VERSION ""

NS_ :

BS_:

BU_: Inverter_A Inverter_B MCU_Aux_A MCU_Aux_B CLU

BO_ 3221225472 VECTOR__INDEPENDENT_SIG_MSG: 0 Vector__XXX
 SG_ TurnOnOff : 0|8@1+ (1,0) [0|0] ""  Inverter_B
 SG_ Tuning_8 : 56|8@1+ (1,0) [0|0] ""  Inverter_A
 SG_ Tuning_7 : 48|8@1+ (1,0) [0|0] ""  Inverter_A
 SG_ Tuning_8 : 56|8@1+ (1,0) [0|0] ""  Inverter_B
 SG_ Tuning_7 : 48|8@1+ (1,0) [0|0] ""  Inverter_B
 SG_ TempPH2 : 0|1@1+ (1,0) [0|0] "degC" Vector__XXX
 SG_ TempPH3 : 0|1@1+ (1,0) [0|0] "degC" Vector__XXX

BO_ 16 TurnOnOffM1: 1 CLU
 SG_ Init : 0|1@1+ (1,0) [0|0] ""  Inverter_A
 SG_ Modulate : 1|1@1+ (1,0) [0|0] ""  Inverter_A

BO_ 32 TorqueReqSpeedLimitM1: 8 CLU
 SG_ Torque_Req : 0|32@1- (1000,0) [0|0] "Nm"  Inverter_A
 SG_ Speed_Req : 32|32@1- (1000,0) [0|0] "RPS"  Inverter_A

BO_ 33 TorqueReqSpeedLimitM2: 8 CLU
 SG_ Torque_Req : 0|32@1- (1000,0) [0|0] "Nm"  Inverter_B
 SG_ Speed_Req : 32|32@1- (1000,0) [0|0] "RPS"  Inverter_B

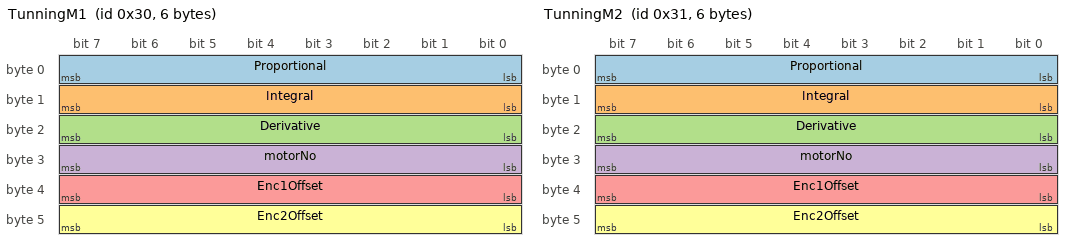
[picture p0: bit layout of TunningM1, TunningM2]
BO_ 48 TunningM1: 6 CLU
 SG_ Proportional : 0|8@1+ (100,0) [0|0] ""  Inverter_A
 SG_ Integral : 8|8@1+ (100,0) [0|0] ""  Inverter_A
 SG_ Derivative : 16|8@1+ (100,0) [0|0] ""  Inverter_A
 SG_ motorNo : 24|8@1+ (1,256) [0|0] ""  Inverter_A
 SG_ Enc1Offset : 32|8@1+ (1,256) [0|0] "LSB"  Inverter_A
 SG_ Enc2Offset : 40|8@1+ (1,256) [0|0] "LSB"  Inverter_A

BO_ 49 TunningM2: 6 CLU
 SG_ Proportional : 0|8@1+ (100,0) [0|0] ""  Inverter_B
 SG_ Integral : 8|8@1+ (100,0) [0|0] ""  Inverter_B
 SG_ Derivative : 16|8@1+ (100,0) [0|0] ""  Inverter_B
 SG_ motorNo : 24|8@1+ (1,0) [0|0] ""  Inverter_B
 SG_ Enc1Offset : 32|8@1+ (1,256) [0|0] "LSB"  Inverter_B
 SG_ Enc2Offset : 40|8@1+ (1,256) [0|0] "LSB"  Inverter_B

BO_ 256 FlowSensorM1: 8 MCU_Aux_A

BO_ 257 FlowSensorM2: 8 MCU_Aux_B

BO_ 64 TorqueDBrakingM1: 8 Inverter_A
 SG_ Torque_D_Output : 0|32@1- (1000,0) [0|0] "Nm"  Inverter_A,CLU

BO_ 65 TorqueDBrakingM2: 8 Inverter_B
 SG_ Torque_D_Output : 0|32@1- (1000,0) [0|0] "Nm"  Inverter_B,CLU

BO_ 80 TorqueSpeedAchievedM1: 8 Inverter_A
 SG_ Torque : 0|32@1- (1000,0) [0|0] "Nm"  CLU
 SG_ Speed : 32|32@1- (1000,0) [0|0] "RPS"  CLU

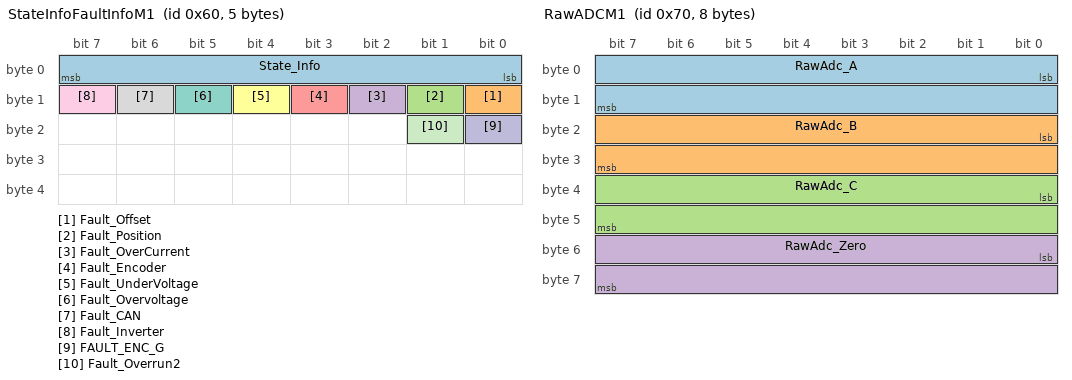
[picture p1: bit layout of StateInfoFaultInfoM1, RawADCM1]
BO_ 96 StateInfoFaultInfoM1: 5 Inverter_A
 SG_ State_Info : 0|8@1- (1,0) [0|0] ""  CLU
 SG_ Fault_Offset : 8|1@1- (1,0) [0|0] ""  CLU
 SG_ Fault_Position : 9|1@1+ (1,0) [0|0] ""  CLU
 SG_ Fault_OverCurrent : 10|1@1+ (1,0) [0|0] ""  CLU
 SG_ Fault_Encoder : 11|1@1+ (1,0) [0|0] ""  CLU
 SG_ Fault_UnderVoltage : 12|1@1+ (1,0) [0|0] ""  CLU
 SG_ Fault_Overvoltage : 13|1@1+ (1,0) [0|0] ""  CLU
 SG_ Fault_CAN : 14|1@1+ (1,0) [0|0] ""  CLU
 SG_ Fault_Inverter : 15|1@1+ (1,0) [0|0] ""  CLU
 SG_ FAULT_ENC_G : 16|1@1+ (1,0) [0|0] ""  CLU
 SG_ Fault_Overrun2 : 17|1@1+ (1,0) [0|0] ""  CLU

BO_ 112 RawADCM1: 8 Inverter_A
 SG_ RawAdc_A : 0|16@1+ (1,0) [0|0] ""  CLU
 SG_ RawAdc_B : 16|16@1+ (1,0) [0|0] ""  CLU
 SG_ RawAdc_C : 32|16@1+ (1,0) [0|0] ""  CLU
 SG_ RawAdc_Zero : 48|16@1- (1,0) [0|0] ""  CLU

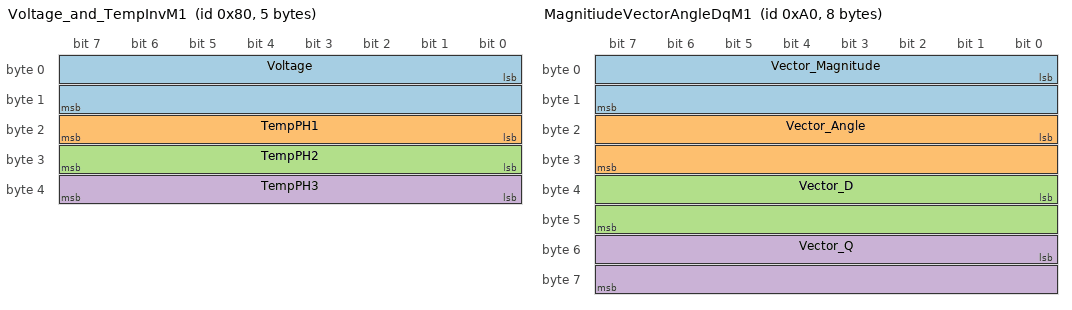
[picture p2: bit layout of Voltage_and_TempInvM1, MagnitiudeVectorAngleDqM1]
BO_ 128 Voltage_and_TempInvM1: 5 Inverter_A
 SG_ Voltage : 0|16@1+ (1,0) [0|0] "V"  CLU
 SG_ TempPH1 : 16|8@1+ (1,0) [0|0] "degC"  CLU
 SG_ TempPH2 : 24|8@1+ (1,0) [0|0] "degC"  CLU
 SG_ TempPH3 : 32|8@1+ (1,0) [0|0] "degC"  CLU

BO_ 160 MagnitiudeVectorAngleDqM1: 8 Inverter_A
 SG_ Vector_Magnitude : 0|16@1- (10000,0) [0|0] ""  CLU
 SG_ Vector_Angle : 16|16@1- (1000,0) [0|0] ""  CLU
 SG_ Vector_D : 32|16@1- (10000,0) [0|0] ""  CLU
 SG_ Vector_Q : 48|16@1- (10000,0) [0|0] ""  CLU

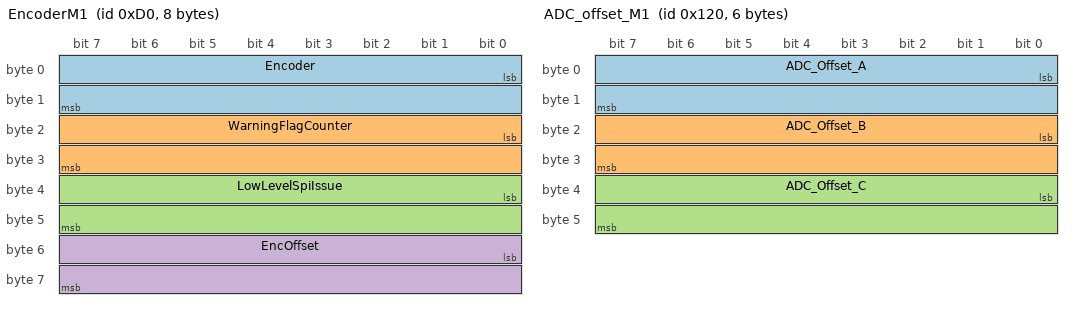
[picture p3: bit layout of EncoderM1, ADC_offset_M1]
BO_ 208 EncoderM1: 8 Inverter_A
 SG_ Encoder : 0|16@1+ (1,0) [0|0] "LSB"  CLU
 SG_ WarningFlagCounter : 16|16@1+ (1,0) [0|0] ""  CLU
 SG_ LowLevelSpiIssue : 32|16@1+ (1,0) [0|0] ""  CLU
 SG_ EncOffset : 48|16@1+ (1,0) [0|0] "LSB"  CLU

BO_ 288 ADC_offset_M1: 6 Inverter_A
 SG_ ADC_Offset_A : 0|16@1+ (1,0) [0|0] ""  CLU
 SG_ ADC_Offset_B : 16|16@1+ (1,0) [0|0] ""  CLU
 SG_ ADC_Offset_C : 32|16@1+ (1,0) [0|0] ""  CLU

BO_ 304 BuildInfo1_M1: 8 Inverter_A
 SG_ SiliconUID : 0|32@1+ (1,0) [0|0] ""  CLU
 SG_ BuildVersionSimulinkAfterDecimal : 32|32@1+ (1,0) [0|0] ""  CLU

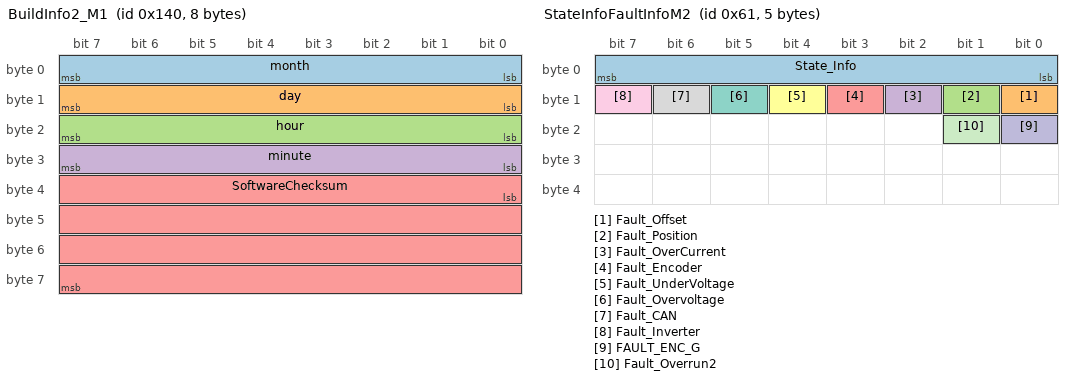
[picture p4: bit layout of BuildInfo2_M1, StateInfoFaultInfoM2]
BO_ 320 BuildInfo2_M1: 8 Inverter_A
 SG_ month : 0|8@1+ (1,0) [0|0] ""  CLU
 SG_ day : 8|8@1+ (1,0) [0|0] ""  CLU
 SG_ hour : 16|8@1+ (1,0) [0|0] ""  CLU
 SG_ minute : 24|8@1+ (1,0) [0|0] ""  CLU
 SG_ SoftwareChecksum : 32|32@1+ (1,0) [0|0] ""  CLU

BO_ 528 PidOutputM1: 8 Inverter_A
 SG_ PID_Output_D : 0|32@1- (1e-09,0) [0|0] "PU"  CLU
 SG_ PID_Output_Q : 32|32@1- (1e-09,0) [0|0] "PU"  CLU

BO_ 81 TorqueSpeedAchievedM2: 8 Inverter_B
 SG_ Torque : 0|32@1- (1000,0) [0|0] "Nm"  CLU
 SG_ Speed : 32|32@1- (1000,0) [0|0] "RPS"  CLU

BO_ 97 StateInfoFaultInfoM2: 5 Inverter_B
 SG_ State_Info : 0|8@1- (1,0) [0|0] ""  CLU
 SG_ Fault_Offset : 8|1@1- (1,0) [0|0] ""  CLU
 SG_ Fault_Position : 9|1@1+ (1,0) [0|0] ""  CLU
 SG_ Fault_OverCurrent : 10|1@1+ (1,0) [0|0] ""  CLU
 SG_ Fault_Encoder : 11|1@1+ (1,0) [0|0] ""  CLU
 SG_ Fault_UnderVoltage : 12|1@1+ (1,0) [0|0] ""  CLU
 SG_ Fault_Overvoltage : 13|1@1+ (1,0) [0|0] ""  CLU
 SG_ Fault_CAN : 14|1@1+ (1,0) [0|0] ""  CLU
 SG_ Fault_Inverter : 15|1@1+ (1,0) [0|0] ""  CLU
 SG_ FAULT_ENC_G : 16|1@1+ (1,0) [0|0] ""  CLU
 SG_ Fault_Overrun2 : 17|1@1+ (1,0) [0|0] ""  CLU

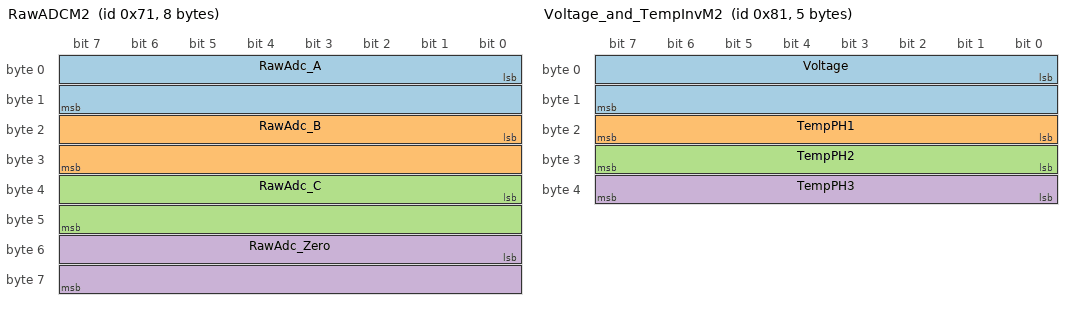
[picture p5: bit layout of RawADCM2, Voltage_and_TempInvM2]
BO_ 113 RawADCM2: 8 Inverter_B
 SG_ RawAdc_A : 0|16@1+ (1,0) [0|0] ""  CLU
 SG_ RawAdc_B : 16|16@1+ (1,0) [0|0] ""  CLU
 SG_ RawAdc_C : 32|16@1+ (1,0) [0|0] ""  CLU
 SG_ RawAdc_Zero : 48|16@1- (1,0) [0|0] ""  CLU

BO_ 129 Voltage_and_TempInvM2: 5 Inverter_B
 SG_ Voltage : 0|16@1+ (1,0) [0|0] "V"  CLU
 SG_ TempPH1 : 16|8@1+ (1,0) [0|0] "degC"  CLU
 SG_ TempPH2 : 24|8@1+ (1,0) [0|0] "degC"  CLU
 SG_ TempPH3 : 32|8@1+ (1,0) [0|0] "degC"  CLU

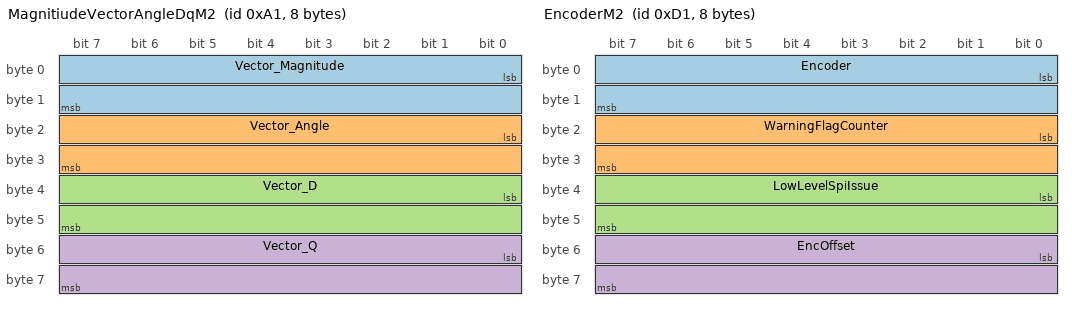
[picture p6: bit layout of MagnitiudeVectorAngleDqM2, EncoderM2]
BO_ 161 MagnitiudeVectorAngleDqM2: 8 Inverter_B
 SG_ Vector_Magnitude : 0|16@1- (10000,0) [0|0] ""  CLU
 SG_ Vector_Angle : 16|16@1- (1000,0) [0|0] ""  CLU
 SG_ Vector_D : 32|16@1- (10000,0) [0|0] ""  CLU
 SG_ Vector_Q : 48|16@1- (10000,0) [0|0] ""  CLU

BO_ 209 EncoderM2: 8 Inverter_B
 SG_ Encoder : 0|16@1+ (1,0) [0|0] "LSB"  CLU
 SG_ WarningFlagCounter : 16|16@1+ (1,0) [0|0] ""  CLU
 SG_ LowLevelSpiIssue : 32|16@1+ (1,0) [0|0] ""  CLU
 SG_ EncOffset : 48|16@1+ (1,0) [0|0] "LSB"  CLU

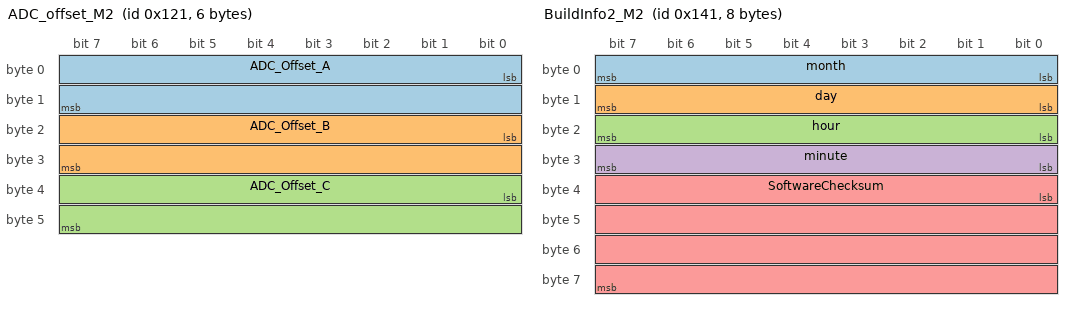
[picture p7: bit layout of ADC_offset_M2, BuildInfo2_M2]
BO_ 289 ADC_offset_M2: 6 Inverter_B
 SG_ ADC_Offset_A : 0|16@1+ (1,0) [0|0] ""  CLU
 SG_ ADC_Offset_B : 16|16@1+ (1,0) [0|0] ""  CLU
 SG_ ADC_Offset_C : 32|16@1+ (1,0) [0|0] ""  CLU

BO_ 305 BuildInfo1_M2: 8 Inverter_B
 SG_ SiliconUID : 0|32@1+ (1,0) [0|0] ""  CLU
 SG_ BuildVersionSimulinkAfterDecimal : 32|32@1+ (1,0) [0|0] ""  CLU

BO_ 321 BuildInfo2_M2: 8 Inverter_B
 SG_ month : 0|8@1+ (1,0) [0|0] ""  CLU
 SG_ day : 8|8@1+ (1,0) [0|0] ""  CLU
 SG_ hour : 16|8@1+ (1,0) [0|0] ""  CLU
 SG_ minute : 24|8@1+ (1,0) [0|0] ""  CLU
 SG_ SoftwareChecksum : 32|32@1+ (1,0) [0|0] ""  CLU

BO_ 529 PidOutputM2: 8 Inverter_B
 SG_ PID_Output_D : 0|32@1- (1e-09,0) [0|0] "PU"  CLU
 SG_ PID_Output_Q : 32|32@1- (1e-09,0) [0|0] "PU"  CLU

BO_ 17 TurnOnOffM2: 1 CLU
 SG_ Init : 0|1@1+ (1,0) [0|0] ""  Inverter_B
 SG_ Modulate : 1|1@1+ (1,0) [0|0] ""  Inverter_B

CM_ BO_ 16 "INV MBOX 0 , CLU MBOX 0";
CM_ BO_ 32 "INV MBOX 2 , CLU MBOX 2";
CM_ BO_ 33 "INV MBOX 2 , CLU MBOX 3";
CM_ BO_ 48 "INV MBOX 4 , CLU MBOX 4";
CM_ BO_ 49 "INV MBOX 4 , CLU MBOX 4";
CM_ BO_ 256 "INV MBOX 11  CLU MBOX 26";
CM_ BO_ 257 "INV MBOX 11  CLU MBOX 27";
CM_ BO_ 64 "INV MBOX 6 , CLU MBOX 6";
CM_ BO_ 65 "INV MBOX 6 , CLU MBOX 7";
CM_ BO_ 80 "INV MBOX 8 , CLU MBOX 8";
CM_ BO_ 96 "INV MBOX 19,10,5,3  CLU MBOX 10";
CM_ BO_ 112 "INV MBOX 12  CLU MBOX 12";
CM_ BO_ 128 "INV MBOX 14  CLU MBOX 14";
CM_ BO_ 160 "INV MBOX 18  CLU MBOX 18";
CM_ BO_ 208 "INV MBOX 24  CLU MBOX 24";
CM_ BO_ 288 "INV MBOX 30  CLU MBOX 30";
CM_ BO_ 304 "INV MBOX 7  CLU MBOX 16";
CM_ SG_ 304 BuildVersionSimulinkAfterDecimal "string";
CM_ BO_ 320 "INV MBOX 9 CLU MBOX 20";
CM_ BO_ 528 "INV MBOX 1 CLU MBOX 22";
CM_ BO_ 81 "INV MBOX 8 , CLU MBOX 9";
CM_ BO_ 97 "INV MBOX 19,10,5,3  CLU MBOX 11";
CM_ BO_ 113 "INV MBOX 12  CLU MBOX 13";
CM_ BO_ 129 "INV MBOX 14  CLU MBOX 15";
CM_ BO_ 161 "INV MBOX 18  CLU MBOX 19";
CM_ BO_ 209 "INV MBOX 24  CLU MBOX 25";
CM_ BO_ 289 "INV MBOX 30  CLU MBOX 31";
CM_ BO_ 305 "INV MBOX 7  CLU MBOX 17";
CM_ SG_ 305 BuildVersionSimulinkAfterDecimal "string";
CM_ BO_ 321 "INV MBOX 9 CLU MBOX 21";
CM_ BO_ 529 "INV MBOX 1 CLU MBOX 23";
CM_ BO_ 17 "INV MBOX 0 , CLU MBOX 1";
